# CC1314R10 register map
File version: 1.0
CPU: CM33 1.0, other endian, MPU, FPU, 3 interrupt priority bits
Registers are 32-bit, read-write, reset 0x0 unless marked. A register's access mark holds for its fields unless they carry their own. Offsets are from the block's base; [hi:lo] are bit positions; lines under a group give offsets from that group; {n}, {i} and the like mark numbered series.

## CPU_ICB — Cortex-M's Implementation Control Block (ICB)
Base 0xE000E000
0x04 ICTR — Provides information about the interrupt controller
  [3:0] INTLINESNUM ro — [3:0] Indicates the number of the highest implemented register in each of the NVIC control register sets, or in the case of NVIC_IPR*n, 4xINTLINESNUM
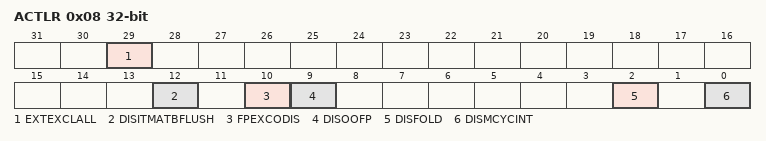
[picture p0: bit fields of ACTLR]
0x08 ACTLR — Provides IMPLEMENTATION DEFINED configuration and control options
  [29] EXTEXCLALL — [29:29] External Exclusives Allowed with no MPU
  [12] DISITMATBFLUSH — [12:12] Disable ATB Flush
  [10] FPEXCODIS — [10:10] Disable FPU exception outputs
  [9] DISOOFP — [9:9] Disable out-of-order FP instruction completion
  [2] DISFOLD — [2:2] Disable dual-issue.
  [0] DISMCYCINT — [0:0] Disable dual-issue.

## CPU_SYSTICK — Cortex-M's System Timer (SYSTICK)
Base 0xE000E010
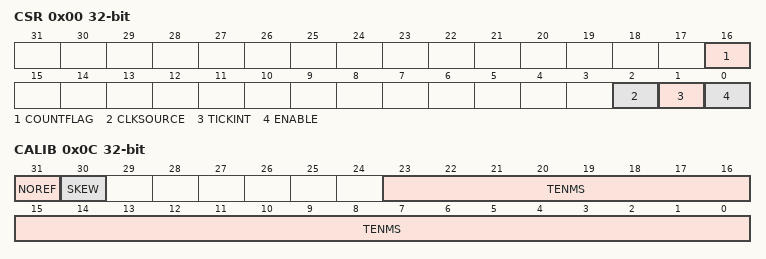
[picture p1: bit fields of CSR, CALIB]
0x00 CSR — Controls the SysTick timer and provides status data `FTSSS
  [16] COUNTFLAG — [16:16] Indicates whether the counter has counted to zero since the last read of this register
  [2] CLKSOURCE — [2:2] Indicates the SysTick clock source
  [1] TICKINT — [1:1] Indicates whether counting to 0 causes the status of the SysTick exception to change to pending
  [0] ENABLE — [0:0] Indicates the enabled status of the SysTick counter
0x04 RVR — Provides access SysTick timer counter reload value `FTSSS
  [23:0] RELOAD — [23:0] The value to load into the SYST_CVR `FTSSS when the counter reaches 0
0x08 CVR — Reads or clears the SysTick timer current counter value `FTSSS
  [23:0] CURRENT wo — [23:0] Writing any value clears the SysTick timer counter `FTSSS to zero
0x0C CALIB — Reads the SysTick timer calibration value and parameters `FTSSS
  [31] NOREF ro — [31:31] Indicates whether the IMPLEMENTATION DEFINED reference clock is implemented
  [30] SKEW ro — [30:30] Indicates whether the 10ms calibration value is exact
  [23:0] TENMS ro — [23:0] Optionally, holds a reload value to be used for 10ms (100Hz) timing, subject to system clock skew errors. If this field is zero, the calibration value is not known

## CPU_NVIC — Cortex-M's Nested Vectored Interrupt Controller (NVIC)
Base 0xE000E100
0x00 ISER0 — Enables or reads the enabled state of each group of 32 interrupts
  [31:0] SETENA ro — [31:0] For SETENA[m] in NVIC_ISER*n, indicates whether interrupt 32*n + m is enabled
0x04 ISER1 — Enables or reads the enabled state of each group of 32 interrupts
  [15:0] SETENA ro — [15:0] For SETENA[m] in NVIC_ISER*n, indicates whether interrupt 32*n + m is enabled
0x80 ICER0 — Clears or reads the enabled state of each group of 32 interrupts
  [31:0] CLRENA ro — [31:0] For CLRENA[m] in NVIC_ICER*n, indicates whether interrupt 32*n + m is enabled
0x84 ICER1 — Clears or reads the enabled state of each group of 32 interrupts
  [15:0] CLRENA ro — [15:0] For CLRENA[m] in NVIC_ICER*n, indicates whether interrupt 32*n + m is enabled
0x100 ISPR0 — Enables or reads the pending state of each group of 32 interrupts
  [31:0] SETPEND ro — [31:0] For SETPEND[m] in NVIC_ISPR*n, indicates whether interrupt 32*n + m is pending
0x104 ISPR1 — Enables or reads the pending state of each group of 32 interrupts
  [15:0] SETPEND ro — [15:0] For SETPEND[m] in NVIC_ISPR*n, indicates whether interrupt 32*n + m is pending
0x180 ICPR0 — Clears or reads the pending state of each group of 32 interrupts
  [31:0] CLRPEND ro — [31:0] For CLRPEND[m] in NVIC_ICPR*n, indicates whether interrupt 32*n + m is pending
0x184 ICPR1 — Clears or reads the pending state of each group of 32 interrupts
  [15:0] CLRPEND ro — [15:0] For CLRPEND[m] in NVIC_ICPR*n, indicates whether interrupt 32*n + m is pending
0x200 IABR0 — For each group of 32 interrupts, shows the active state of each interrupt
  [31:0] ACTIVE ro — [31:0] For ACTIVE[m] in NVIC_IABR*n, indicates the active state for interrupt 32*n+m
0x204 IABR1 — For each group of 32 interrupts, shows the active state of each interrupt
  [15:0] ACTIVE ro — [15:0] For ACTIVE[m] in NVIC_IABR*n, indicates the active state for interrupt 32*n+m
0x280 ITNS0 — For each group of 32 interrupts, determines whether each interrupt targets Non-secure or Secure state
  [31:0] ITNS — [31:0] For ITNS[m] in NVIC_ITNS*n, the target Security state for interrupt 32*n+m
0x284 ITNS1 — For each group of 32 interrupts, determines whether each interrupt targets Non-secure or Secure state
  [15:0] ITNS — [15:0] For ITNS[m] in NVIC_ITNS*n, the target Security state for interrupt 32*n+m
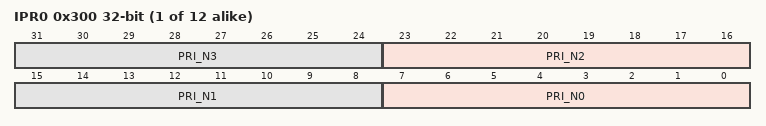
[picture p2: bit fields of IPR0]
{0x300+4i} IPR{i} (i=0..11) — Sets or reads interrupt priorities
  [8n+7:8n] PRI_N{n} (n=0..3) — [{8n+7}:{8n}] For register NVIC_IPR*{i}, the priority of interrupt number 4*{i}+{n}, or is RES0 if the PE does not implement this interrupt
